# tle984x register map
Vendor: Infineon; File version: 1.9.5
CPU: CM0 r2p1, little endian, no MPU, no FPU, 2 interrupt priority bits
Registers are 32-bit, read-write, reset 0x0 unless marked. A register's access mark holds for its fields unless they carry their own. Offsets are from the block's base; [hi:lo] are bit positions; {n}, {i} and the like mark numbered series.

## CPU — CPU processor registers
Base 0xE000E000
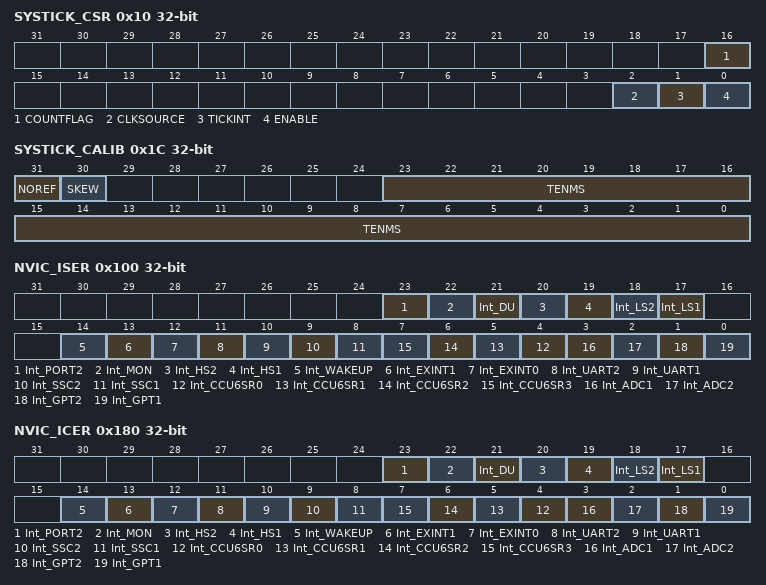
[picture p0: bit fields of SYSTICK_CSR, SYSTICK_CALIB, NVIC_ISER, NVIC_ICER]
0x10 SYSTICK_CSR — SysTick control and status register
  [16] COUNTFLAG ro
  [2] CLKSOURCE
    0=EXTCLK (External reference clock (from fSYS/4)); 1=HCLK (Core clock (from fSYS))
  [1] TICKINT
    0=DISABLE (Counting down to 0 does not assert the SysTick exception request); 1=ENABLE (Counting down to 0 asserts the SysTick exception request)
  [0] ENABLE
    0=DISABLE (Counter disabled); 1=ENABLE (Counter enabled)
0x14 SYSTICK_RVR (reset mask 0xFF000000) — SysTick reload value register
  [23:0] RELOAD
0x18 SYSTICK_CVR (reset mask 0xFF000000) — SysTick current value register
  [23:0] CURRENT
0x1C SYSTICK_CALIB ro (reset mask 0xF000000) — SysTick calibration value register
  [31] NOREF — No reference clock
  [30] SKEW
  [23:0] TENMS
0x100 NVIC_ISER — Interrupt set-enable register
  [all] fields
    0=DISABLED (No effect on write); 1=ENABLE (Enables the associated interrupt)
  [23] Int_PORT2 — Interrupt set for PORT2
  [22] Int_MON — Interrupt set for MON
  [21] Int_DU — Interrupt set for differential unit
  [20] Int_HS2 — Interrupt set for HS2
  [19] Int_HS1 — Interrupt set for HS1
  [18] Int_LS2 — Interrupt set for LS2
  [17] Int_LS1 — Interrupt set for LS1
  [14] Int_WAKEUP — Interrupt set for WAKEUP
  [13] Int_EXINT1 — Interrupt set for external Int 1
  [12] Int_EXINT0 — Interrupt set for external Int 0
  [11] Int_UART2 — Interrupt set for UART2
  [10] Int_UART1 — Interrupt set for UART1
  [9] Int_SSC2 — Interrupt set for SSC2
  [8] Int_SSC1 — Interrupt set for SSC1
  [n+4] Int_CCU6SR{n} (n=0..3) — Interrupt set for CCU6 SR{n}
  [3] Int_ADC1 — Interrupt set for ADC1
  [2] Int_ADC2 — Interrupt set for MU, ADC2
  [1] Int_GPT2 — Interrupt set for GPT2
  [0] Int_GPT1 — Interrupt set for GPT1
0x180 NVIC_ICER — Interrupt clear-enable register
  [all] fields
    0=DISABLE (On reads the associated interrupt is disabled, no effect on write); 1=ENABLE (On reads the associated interrupt is enabled, on writes the associated interrupt is disabled)
  [23] Int_PORT2 — Interrupt Clear for PORT2
  [22] Int_MON — Interrupt clear for MON
  [21] Int_DU — Interrupt clear for differential unit
  [20] Int_HS2 — Interrupt clear for HS2
  [19] Int_HS1 — Interrupt clear for HS1
  [18] Int_LS2 — Interrupt clear for LS2
  [17] Int_LS1 — Interrupt clear for LS1
  [14] Int_WAKEUP — Interrupt clear for WAKEUP
  [13] Int_EXINT1 — Interrupt clear for external Int 1
  [12] Int_EXINT0 — Interrupt clear for external Int 0
  [11] Int_UART2 — Interrupt clear for UART2
  [10] Int_UART1 — Interrupt clear for UART1
  [9] Int_SSC2 — Interrupt clear for SSC2
  [8] Int_SSC1 — Interrupt clear for SSC1
  [n+4] Int_CCU6SR{n} (n=0..3) — Interrupt clear for CCU6 SR{n}
  [3] Int_ADC1 — Interrupt clear for ADC1
  [2] Int_ADC2 — Interrupt clear for MU, ADC2
  [1] Int_GPT2 — Interrupt clear for GPT2
  [0] Int_GPT1 — Interrupt clear for GPT1
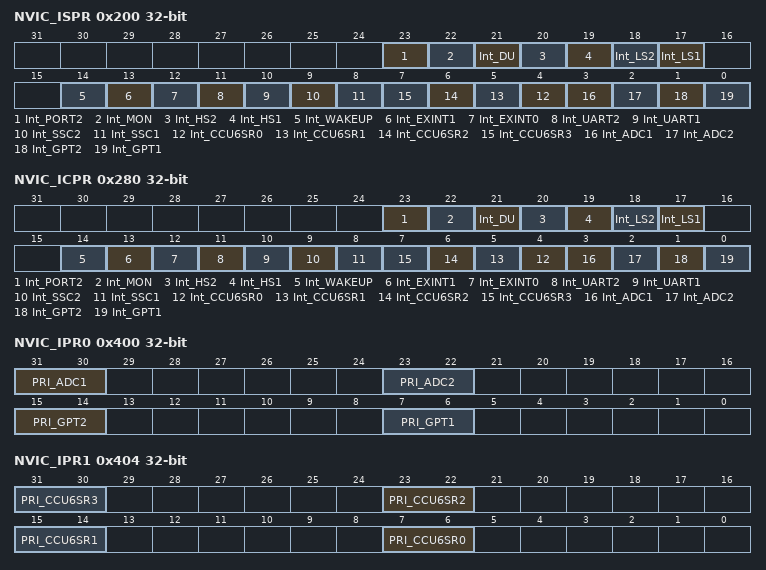
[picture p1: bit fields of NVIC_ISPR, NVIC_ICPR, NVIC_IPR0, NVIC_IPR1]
0x200 NVIC_ISPR — Interrupt set-pending register
  [all] fields
    0=Not_pending (On reads the associated interrupt is not pending, no effect on writes); 1=Pending (The associated interrupt is pending)
  [23] Int_PORT2 — Interrupt set pending for PORT2
  [22] Int_MON — Interrupt set pending for MON
  [21] Int_DU — Interrupt set pending for differential unit
  [20] Int_HS2 — Interrupt set pending for HS2
  [19] Int_HS1 — Interrupt set pending for HS1
  [18] Int_LS2 — Interrupt set pending for LS2
  [17] Int_LS1 — Interrupt set pending for LS1
  [14] Int_WAKEUP — Interrupt set pending for WAKEUP
  [13] Int_EXINT1 — Interrupt set pending for external Int 1
  [12] Int_EXINT0 — Interrupt set pending for external Int 0
  [11] Int_UART2 — Interrupt set pending for UART2
  [10] Int_UART1 — Interrupt set pending for UART1
  [9] Int_SSC2 — Interrupt set pending for SSC2
  [8] Int_SSC1 — Interrupt set pending for SSC1
  [n+4] Int_CCU6SR{n} (n=0..3) — Interrupt set pending for CCU6 SR{n}
  [3] Int_ADC1 — Interrupt set pending for ADC1
  [2] Int_ADC2 — Interrupt set pending for MU, ADC2
  [1] Int_GPT2 — Interrupt set pending for GPT2
  [0] Int_GPT1 — Interrupt set pending for GPT1
0x280 NVIC_ICPR — Interrupt clear-pending register
  [all] fields
    0=Not_pending (On reads the associated interrupt is not pending, no effect on writes); 1=Pending (On reads the associated interrupt is pending, on writes the status of the associated interrupt is changed to not pending)
  [23] Int_PORT2 — Interrupt clear pending for PORT2
  [22] Int_MON — Interrupt clear pending for MON
  [21] Int_DU — Interrupt clear pending for differential unit
  [20] Int_HS2 — Interrupt clear pending for HS2
  [19] Int_HS1 — Interrupt clear pending for HS1
  [18] Int_LS2 — Interrupt clear pending for LS2
  [17] Int_LS1 — Interrupt clear pending for LS1
  [14] Int_WAKEUP — Interrupt clear pending for WAKEUP
  [13] Int_EXINT1 — Interrupt clear pending for external Int 1
  [12] Int_EXINT0 — Interrupt clear pending for external Int 0
  [11] Int_UART2 — Interrupt clear pending for UART2
  [10] Int_UART1 — Interrupt clear pending for UART1
  [9] Int_SSC2 — Interrupt clear pending for SSC2
  [8] Int_SSC1 — Interrupt clear pending for SSC1
  [n+4] Int_CCU6SR{n} (n=0..3) — Interrupt clear pending for CCU6 SR{n}
  [3] Int_ADC1 — Interrupt clear pending for ADC1
  [2] Int_ADC2 — Interrupt clear pending for MU, ADC2
  [1] Int_GPT2 — Interrupt clear pending for GPT2
  [0] Int_GPT1 — Interrupt clear pending for GPT1
0x400 NVIC_IPR0 — Interrupt priority 0 register
  [31:30] PRI_ADC1 — Priority for ADC1
  [23:22] PRI_ADC2 — Priority for MU, ADC2
  [15:14] PRI_GPT2 — Priority for GPT2
  [7:6] PRI_GPT1 — Priority for GPT1
0x404 NVIC_IPR1 — Interrupt priority 1 register
  [8n+7:8n+6] PRI_CCU6SR{n} (n=0..3) — Priority for CCU6 SR{n}
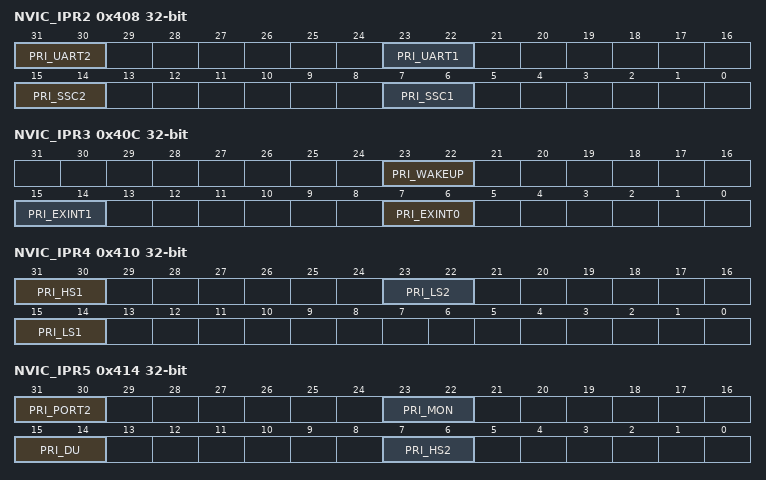
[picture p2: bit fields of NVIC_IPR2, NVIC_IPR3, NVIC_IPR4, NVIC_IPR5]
0x408 NVIC_IPR2 — Interrupt priority 2 register
  [31:30] PRI_UART2 — Priority for CCU6 UART2
  [23:22] PRI_UART1 — Priority for CCU6 UART1
  [15:14] PRI_SSC2 — Priority for CCU6 SSC2
  [7:6] PRI_SSC1 — Priority for CCU6 SSC1
0x40C NVIC_IPR3 — Interrupt priority 3 register
  [23:22] PRI_WAKEUP — Priority for WAKEUP
  [15:14] PRI_EXINT1 — Priority for external Int 1
  [7:6] PRI_EXINT0 — Priority for external Int 0
0x410 NVIC_IPR4 — Interrupt priority 4 register
  [31:30] PRI_HS1 — Priority for HS1
  [23:22] PRI_LS2 — Priority for LS2
  [15:14] PRI_LS1 — Priority for LS1
0x414 NVIC_IPR5 — Interrupt priority 5 register
  [31:30] PRI_PORT2 — Priority for PORT2
  [23:22] PRI_MON — Priority for MON
  [15:14] PRI_DU — Priority for differential unit
  [7:6] PRI_HS2 — Priority for HS2
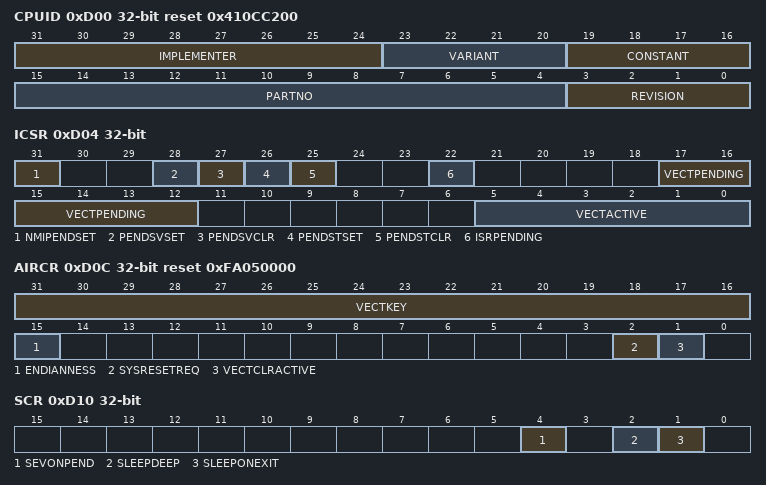
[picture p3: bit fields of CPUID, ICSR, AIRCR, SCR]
0xD00 CPUID ro reset 0x410CC200 — CPU ID base register
  [31:24] IMPLEMENTER — Implementer code
  [23:20] VARIANT — Variant number
  [19:16] CONSTANT
  [15:4] PARTNO — Part number
  [3:0] REVISION — Revision number
0xD04 ICSR — Interrupt control and state register
  [31] NMIPENDSET — NMI set pending
    0=NOT_PENDING (On writes, has no effect. On reads, NMI exception is not pending); 1=PENDING (On writes, changes the NMI exception state to pending. On reads, NMI exception is pending)
  [28] PENDSVSET — PendSV set pending
    0=NOT_PENDING (On writes, has no effect. On reads, PendSV exception is not pending); 1=PENDING (On writes, changes PendSV exception state to pending. On reads, PendSV is pending)
  [27] PENDSVCLR wo — PendSV clear pending
    0=NO_EFFECT; 1=CLEAR (Remove pending state from the PENDSV exception)
  [26] PENDSTSET — SysTick exception set pending
    0=NOT_PENDING (On writes, has no effect. On reads, SysTick exception is not pending); 1=PENDING (On writes, changes SysTick exception state to pending. On reads, SysTick exception is pending)
  [25] PENDSTCLR wo — SysTick exception clear pending
    0=NO_EFFECT; 1=REMOVE (Removes the pending state from the SysTick exception)
  [22] ISRPENDING ro — Interrupt pending flag
    0=NOT_PENDING (Interrupt not pending); 1=PENDING (Interrupt is pending)
  [17:12] VECTPENDING ro
    0=NOT_PENDING (No pending exceptions)
  [5:0] VECTACTIVE ro — VECTACTIVATE
    0=THREAD (Thread mode)
0xD0C AIRCR reset 0xFA050000 — Application interrupt/reset control register
  [31:16] VECTKEY — Vector key
  [15] ENDIANNESS ro — Data endianness
    0=LITTLE_ENDIAN; 1=BIG_ENDIAN
  [2] SYSRESETREQ wo — System reset request
    0=NO_EFFECT; 1=RESET (Request a system level reset)
  [1] VECTCLRACTIVE wo
0xD10 SCR — System control register
  [4] SEVONPEND — Send event on pending bit
    0=SOME (Only enabled interrupts or events can wake-up the processor, disabled interrupts are excluded); 1=ALL (Enabled events and all interrupts, including disabled interrupts, can wake up the processor)
  [2] SLEEPDEEP
    0=SLEEP; 1=DEEP_SLEEP
  [1] SLEEPONEXIT
    0=NO_SLEEP (Do not sleep when returning to Thread mode); 1=SLEEP (Enter sleep or deep sleep on return from an ISR to Thread mode)
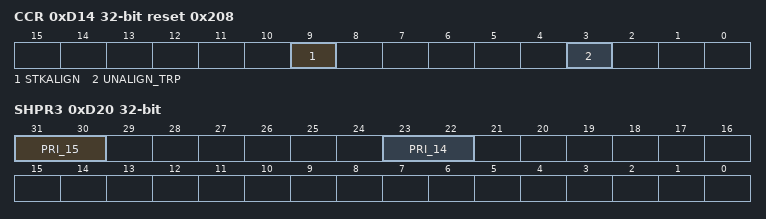
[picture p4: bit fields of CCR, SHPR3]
0xD14 CCR ro reset 0x208 — Configuration control register
  [9] STKALIGN, [3] UNALIGN_TRP
0xD1C SHPR2 — System handler priority 2 register
  [31:30] PRI_11 — Priority of system handler 11, SVCall
0xD20 SHPR3 — System handler priority 3 register
  [31:30] PRI_15 — Priority of system handler 15, SysTick
  [23:22] PRI_14 — Priority of system handler 14, PendSV
